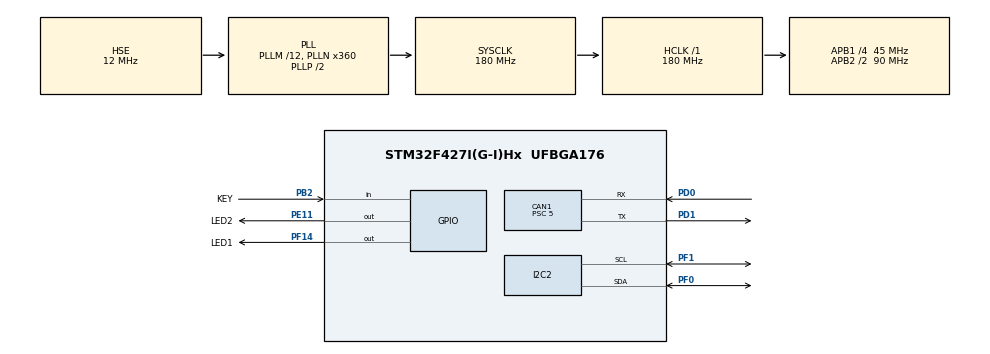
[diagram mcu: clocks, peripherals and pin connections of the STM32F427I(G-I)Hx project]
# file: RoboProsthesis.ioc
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CAN1.BS1=CAN_BS1_3TQ
CAN1.BS2=CAN_BS2_5TQ
CAN1.CalculateBaudRate=1000000
CAN1.CalculateTimeBit=1000
CAN1.CalculateTimeQuantum=111.11111111111111
CAN1.NART=ENABLE
CAN1.Prescaler=5
FREERTOS.Tasks01=defaultTask,0,256,StartDefaultTask,Default,NULL,Dynamic,NULL,NULL
FREERTOS.configUSE_NEWLIB_REENTRANT=1
I2C2.I2C_Mode=I2C_Fast
Mcu.Family=STM32F4
Mcu.Name=STM32F427I(G-I)Hx
Mcu.Package=UFBGA176
NVIC.CAN1_RX0_IRQn=true\:5\:0\:false\:false\:true\:true\:true\:true\:true
NVIC.CAN1_TX_IRQn=true\:5\:0\:false\:false\:true\:true\:true\:true\:true
NVIC.PriorityGroup=NVIC_PRIORITYGROUP_4
NVIC.TIM6_DAC_IRQn=true\:15\:0\:false\:false\:true\:false\:false\:true\:true
NVIC.TimeBase=TIM6_DAC_IRQn
NVIC.TimeBaseIP=TIM6
PA13.Signal=SYS_JTMS-SWDIO
PA14.Signal=SYS_JTCK-SWCLK
PB2/BOOT1.GPIO_Label=KEY
PB2/BOOT1.GPIO_PuPd=GPIO_PULLDOWN
PB2/BOOT1.Signal=GPIO_Input
PD0.Mode=CAN_Activate
PD0.Signal=CAN1_RX
PD1.Mode=CAN_Activate
PD1.Signal=CAN1_TX
PE11.GPIO_Label=LED2
PE11.PinState=GPIO_PIN_SET
PE11.Signal=GPIO_Output
PF0.Mode=I2C
PF0.Signal=I2C2_SDA
PF1.Mode=I2C
PF1.Signal=I2C2_SCL
PF14.GPIO_Label=LED1
PF14.PinState=GPIO_PIN_SET
PF14.Signal=GPIO_Output
PH0/OSC_IN.Mode=HSE-External-Oscillator
PH0/OSC_IN.Signal=RCC_OSC_IN
PH1/OSC_OUT.Mode=HSE-External-Oscillator
PH1/OSC_OUT.Signal=RCC_OSC_OUT
ProjectManager.HeapSize=0x200
ProjectManager.StackSize=0x400
ProjectManager.TargetToolchain=STM32CubeIDE
RCC.48MHZClocksFreq_Value=90000000
RCC.AHBFreq_Value=180000000
RCC.APB1CLKDivider=RCC_HCLK_DIV4
RCC.APB1Freq_Value=45000000
RCC.APB1TimFreq_Value=90000000
RCC.APB2CLKDivider=RCC_HCLK_DIV2
RCC.APB2Freq_Value=90000000
RCC.APB2TimFreq_Value=180000000
RCC.CortexFreq_Value=180000000
RCC.HCLKFreq_Value=180000000
RCC.HSE_VALUE=12000000
RCC.HSI_VALUE=16000000
RCC.LSE_VALUE=32768
RCC.PLLM=12
RCC.PLLN=360
RCC.PLLSourceVirtual=RCC_PLLSOURCE_HSE
RCC.SYSCLKFreq_VALUE=180000000
RCC.SYSCLKSource=RCC_SYSCLKSOURCE_PLLCLK
RCC.VCOOutputFreq_Value=360000000
VP_FREERTOS_VS_CMSIS_V1.Mode=CMSIS_V1
VP_SYS_VS_tim6.Mode=TIM6
board=custom

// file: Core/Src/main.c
/* USER CODE BEGIN Header */
/**
  ******************************************************************************
  * @file           : main.c
  * @brief          : Main program body
  ******************************************************************************
  * @attention
  * - FreeRTOS task creation is placed in freertos.c::MX_FREERTOS_Init() (keep defaultTask)
  * - Peripheral initialization is still generated by Cube (I2C2, CAN1)
  * - LED is off at high level: keep Cube’s default Output Level (high)
  * - Custom CAN filter/start is placed in USER CODE 2 to avoid being overwritten
  ******************************************************************************
  */
/* USER CODE END Header */
#include "main.h"
#include "cmsis_os.h"
#include "can.h"
#include "i2c.h"
#include "gpio.h"

/* USER CODE BEGIN Includes */
#include "bsp_can.h"
/* USER CODE END Includes */

void SystemClock_Config(void);
void MX_FREERTOS_Init(void);

int main(void)
{

  /* MCU Configuration--------------------------------------------------------*/

  /* Reset all peripherals, initialize the Flash interface and the Systick. */
  HAL_Init();

  /* Configure the system clock */
  SystemClock_Config();

  /* Initialize all configured peripherals */
  MX_GPIO_Init();
  MX_CAN1_Init();
  MX_I2C2_Init();
  /* USER CODE BEGIN 2 */
  /* —— Custom CAN: filter + start + interrupt —— */
  my_can_filter_init_recv_all(&hcan1);
  HAL_CAN_Start(&hcan1);
  HAL_CAN_ActivateNotification(&hcan1, CAN_IT_RX_FIFO0_MSG_PENDING);
  /* USER CODE END 2 */

  /* Call init function for FreeRTOS objects (in cmsis_os2.c) */
  MX_FREERTOS_Init();

  /* Start scheduler */
  osKernelStart();

  /* We should never get here as control is now taken by the scheduler */

  /* Infinite loop */
  while (1)
  {

  }
}

void SystemClock_Config(void)
{
  RCC_OscInitTypeDef RCC_OscInitStruct = {0};
  RCC_ClkInitTypeDef RCC_ClkInitStruct = {0};

  /** Configure the main internal regulator output voltage
  */
  __HAL_RCC_PWR_CLK_ENABLE();
  __HAL_PWR_VOLTAGESCALING_CONFIG(PWR_REGULATOR_VOLTAGE_SCALE1);

  /** Initializes the RCC Oscillators according to the specified parameters
  * in the RCC_OscInitTypeDef structure.
  */
  RCC_OscInitStruct.OscillatorType = RCC_OSCILLATORTYPE_HSE;
  RCC_OscInitStruct.HSEState = RCC_HSE_ON;
  RCC_OscInitStruct.PLL.PLLState = RCC_PLL_ON;
  RCC_OscInitStruct.PLL.PLLSource = RCC_PLLSOURCE_HSE;
  RCC_OscInitStruct.PLL.PLLM = 12;
  RCC_OscInitStruct.PLL.PLLN = 360;
  RCC_OscInitStruct.PLL.PLLP = RCC_PLLP_DIV2;
  RCC_OscInitStruct.PLL.PLLQ = 4;
  if (HAL_RCC_OscConfig(&RCC_OscInitStruct) != HAL_OK)
  {
    Error_Handler();
  }

  /** Activate Over-Drive mode
  */
  if (HAL_PWREx_EnableOverDrive() != HAL_OK)
  {
    Error_Handler();
  }

  /** Initializes the CPU, AHB and APB buses clocks
  */
  RCC_ClkInitStruct.ClockType = RCC_CLOCKTYPE_HCLK|RCC_CLOCKTYPE_SYSCLK
                              |RCC_CLOCKTYPE_PCLK1|RCC_CLOCKTYPE_PCLK2;
  RCC_ClkInitStruct.SYSCLKSource = RCC_SYSCLKSOURCE_PLLCLK;
  RCC_ClkInitStruct.AHBCLKDivider = RCC_SYSCLK_DIV1;
  RCC_ClkInitStruct.APB1CLKDivider = RCC_HCLK_DIV4;
  RCC_ClkInitStruct.APB2CLKDivider = RCC_HCLK_DIV2;

  if (HAL_RCC_ClockConfig(&RCC_ClkInitStruct, FLASH_LATENCY_5) != HAL_OK)
  {
    Error_Handler();
  }
}

void HAL_TIM_PeriodElapsedCallback(TIM_HandleTypeDef *htim)
{
  if (htim->Instance == TIM6)
  {
    HAL_IncTick();
  }
}

void Error_Handler(void)
{
  /* USER CODE BEGIN Error_Handler_Debug */
  __disable_irq();
  while (1) {
    /* You can blink an LED here to indicate error */
  }
  /* USER CODE END Error_Handler_Debug */
}
#ifdef USE_FULL_ASSERT
/**
  * @brief  Reports the name of the source file and the source line number
  *         where the assert_param error has occurred.
  * @param  file: pointer to the source file name
  * @param  line: assert_param error line source number
  * @retval None
  */
void assert_failed(uint8_t *file, uint32_t line)
{
  /* USER CODE BEGIN 6 */
  (void)file; (void)line;
  /* USER CODE END 6 */
}
#endif /* USE_FULL_ASSERT */

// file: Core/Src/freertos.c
/* USER CODE BEGIN Header */
/**
  ******************************************************************************
  * File Name          : freertos.c
  * Description        : Code for FreeRTOS applications (App separated)
  ******************************************************************************
  * @attention
  * Copyright (c) 2025 STMicroelectronics.
  * All rights reserved.
  *
  * This software is licensed under terms that can be found in the LICENSE file
  * in the root directory of this software component.
  * If no LICENSE file comes with this software, it is provided AS-IS.
  ******************************************************************************
  */
/* USER CODE END Header */

#include "FreeRTOS.h"
#include "task.h"
#include "main.h"
#include "cmsis_os.h"

/* USER CODE BEGIN Includes */
#include "app_control.h"   /* Business logic entry: app_control_start() */
/* USER CODE END Includes */

osThreadId defaultTaskHandle;

void StartDefaultTask(void const * argument);

void MX_FREERTOS_Init(void); /* (MISRA C 2004 rule 8.1) */

/* GetIdleTaskMemory prototype (linked to static allocation support) */
void vApplicationGetIdleTaskMemory( StaticTask_t **ppxIdleTaskTCBBuffer, StackType_t **ppxIdleTaskStackBuffer, uint32_t *pulIdleTaskStackSize );

/* USER CODE BEGIN GET_IDLE_TASK_MEMORY */
static StaticTask_t xIdleTaskTCBBuffer;
static StackType_t xIdleStack[configMINIMAL_STACK_SIZE];

void vApplicationGetIdleTaskMemory( StaticTask_t **ppxIdleTaskTCBBuffer,
                                    StackType_t **ppxIdleTaskStackBuffer,
                                    uint32_t *pulIdleTaskStackSize )
{
  *ppxIdleTaskTCBBuffer = &xIdleTaskTCBBuffer;
  *ppxIdleTaskStackBuffer = &xIdleStack[0];
  *pulIdleTaskStackSize = configMINIMAL_STACK_SIZE;
}
/* USER CODE END GET_IDLE_TASK_MEMORY */

void MX_FREERTOS_Init(void) {
  /* USER CODE BEGIN Init */
  /* Usually no business logic here, just simple initialization */
  /* USER CODE END Init */

  /* Create the thread(s) */
  /* definition and creation of defaultTask */
  osThreadDef(defaultTask, StartDefaultTask, osPriorityNormal, 0, 256);
  defaultTaskHandle = osThreadCreate(osThread(defaultTask), NULL);

  /* USER CODE BEGIN RTOS_THREADS */
  /* Default task created, entry function StartDefaultTask */
  /* USER CODE END RTOS_THREADS */

}

void StartDefaultTask(void const * argument)
{
  /* USER CODE BEGIN StartDefaultTask */
  /* Launch your business logic loop */
  app_control_start();

  /* If app_control_start() contains an infinite loop,
     control will not return here.
     If it only does initialization, you can continue adding code below. */
  /* USER CODE END StartDefaultTask */
}

/* USER CODE BEGIN Application */

/* Do not place motor business logic here; keep it all in app_control.c */
/* USER CODE END Application */
